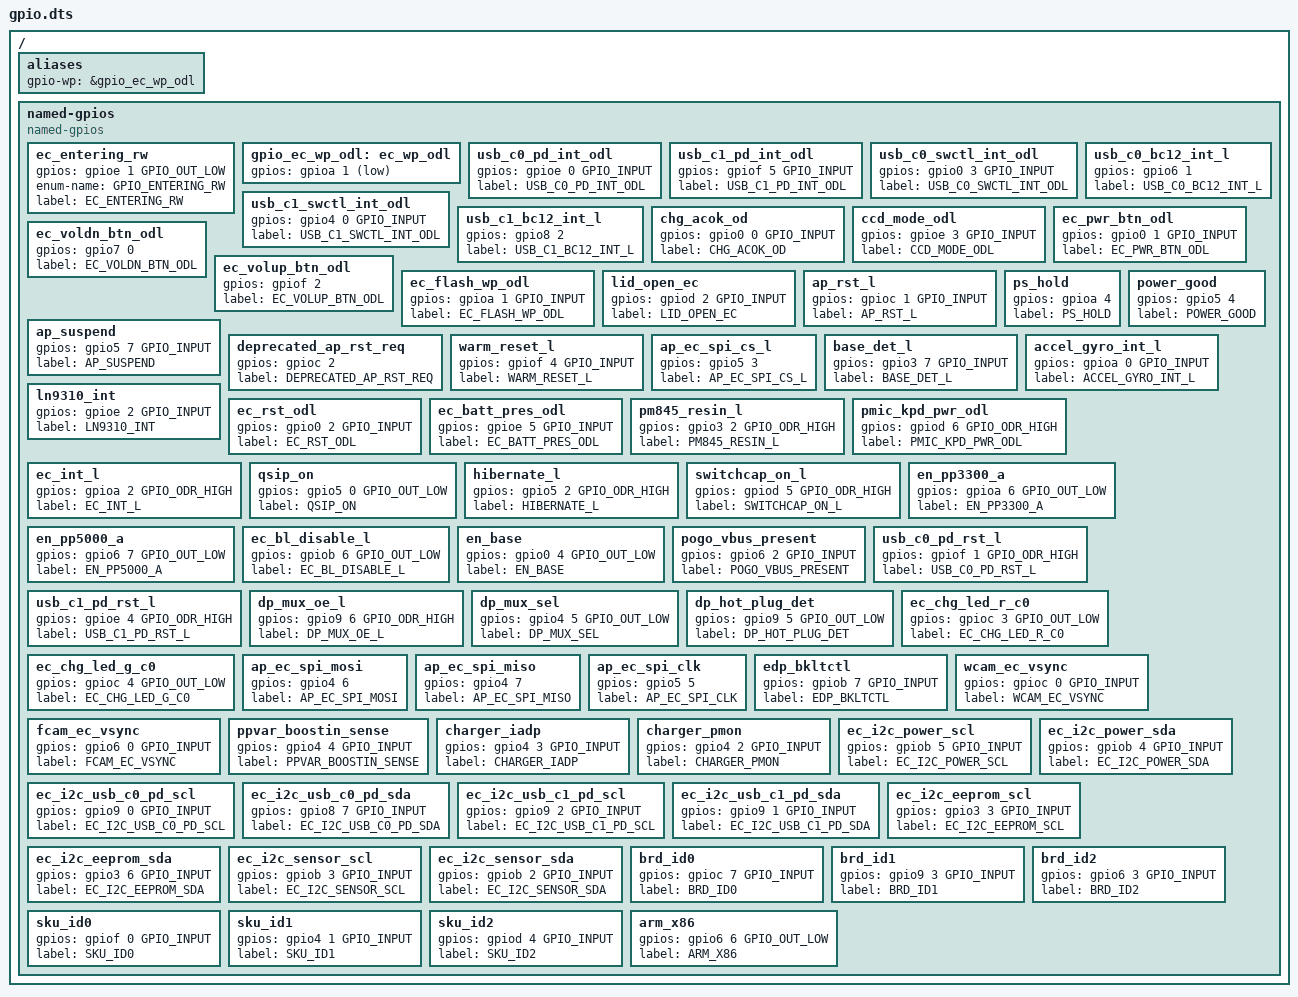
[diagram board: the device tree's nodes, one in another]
/* Copyright 2022 The Chromium OS Authors. All rights reserved.
 * Use of this source code is governed by a BSD-style license that can be
 * found in the LICENSE file.
 */

/ {
	aliases {
		gpio-wp = &gpio_ec_wp_odl;
	};

	named-gpios {
		compatible = "named-gpios";

		ec_entering_rw {
			gpios = <&gpioe 1 GPIO_OUTPUT_LOW>;
			enum-name = "GPIO_ENTERING_RW";
		};
		gpio_ec_wp_odl: ec_wp_odl {
			gpios = <&gpioa 1 (GPIO_INPUT | GPIO_ACTIVE_LOW)>;
		};
		usb_c0_pd_int_odl {
			gpios = <&gpioe 0 GPIO_INPUT>;
			label = "USB_C0_PD_INT_ODL";
		};
		usb_c1_pd_int_odl {
			gpios = <&gpiof 5 GPIO_INPUT>;
			label = "USB_C1_PD_INT_ODL";
		};
		usb_c0_swctl_int_odl {
			gpios = <&gpio0 3 GPIO_INPUT>;
			label = "USB_C0_SWCTL_INT_ODL";
		};
		usb_c1_swctl_int_odl {
			gpios = <&gpio4 0 GPIO_INPUT>;
			label = "USB_C1_SWCTL_INT_ODL";
		};
		usb_c0_bc12_int_l {
			gpios = <&gpio6 1 (GPIO_INPUT | GPIO_PULL_UP)>;
			label = "USB_C0_BC12_INT_L";
		};
		usb_c1_bc12_int_l {
			gpios = <&gpio8 2 (GPIO_INPUT | GPIO_PULL_UP)>;
			label = "USB_C1_BC12_INT_L";
		};
		chg_acok_od {
			gpios = <&gpio0 0 GPIO_INPUT>;
			label = "CHG_ACOK_OD";
		};
		ccd_mode_odl {
			gpios = <&gpioe 3 GPIO_INPUT>;
			label = "CCD_MODE_ODL";
		};
		ec_pwr_btn_odl {
			gpios = <&gpio0 1 GPIO_INPUT>;
			label = "EC_PWR_BTN_ODL";
		};
		ec_voldn_btn_odl {
			gpios = <&gpio7 0 (GPIO_INPUT | GPIO_PULL_UP)>;
			label = "EC_VOLDN_BTN_ODL";
		};
		ec_volup_btn_odl {
			gpios = <&gpiof 2 (GPIO_INPUT | GPIO_PULL_UP)>;
			label = "EC_VOLUP_BTN_ODL";
		};
		ec_flash_wp_odl {
			gpios = <&gpioa 1 GPIO_INPUT>;
			label = "EC_FLASH_WP_ODL";
		};
		lid_open_ec {
			gpios = <&gpiod 2 GPIO_INPUT>;
			label = "LID_OPEN_EC";
		};
		ap_rst_l {
			gpios = <&gpioc 1 GPIO_INPUT>;
			label = "AP_RST_L";
		};
		ps_hold {
			gpios = <&gpioa 4 (GPIO_INPUT | GPIO_PULL_DOWN)>;
			label = "PS_HOLD";
		};
		ap_suspend {
			gpios = <&gpio5 7 GPIO_INPUT>;
			label = "AP_SUSPEND";
		};
		deprecated_ap_rst_req {
			gpios = <&gpioc 2 (GPIO_INPUT | GPIO_PULL_DOWN)>;
			label = "DEPRECATED_AP_RST_REQ";
		};
		power_good {
			gpios = <&gpio5 4 (GPIO_INPUT | GPIO_PULL_DOWN)>;
			label = "POWER_GOOD";
		};
		warm_reset_l {
			gpios = <&gpiof 4 GPIO_INPUT>;
			label = "WARM_RESET_L";
		};
		ap_ec_spi_cs_l {
			gpios = <&gpio5 3 (GPIO_INPUT | GPIO_PULL_DOWN)>;
			label = "AP_EC_SPI_CS_L";
		};
		base_det_l {
			gpios = <&gpio3 7 GPIO_INPUT>;
			label = "BASE_DET_L";
		};
		accel_gyro_int_l {
			gpios = <&gpioa 0 GPIO_INPUT>;
			label = "ACCEL_GYRO_INT_L";
		};
		ln9310_int {
			gpios = <&gpioe 2 GPIO_INPUT>;
			label = "LN9310_INT";
		};
		ec_rst_odl {
			gpios = <&gpio0 2 GPIO_INPUT>;
			label = "EC_RST_ODL";
		};
		ec_entering_rw {
			gpios = <&gpioe 1 GPIO_OUT_LOW>;
			label = "EC_ENTERING_RW";
		};
		ec_batt_pres_odl {
			gpios = <&gpioe 5 GPIO_INPUT>;
			label = "EC_BATT_PRES_ODL";
		};
		pm845_resin_l {
			gpios = <&gpio3 2 GPIO_ODR_HIGH>;
			label = "PM845_RESIN_L";
		};
		pmic_kpd_pwr_odl {
			gpios = <&gpiod 6 GPIO_ODR_HIGH>;
			label = "PMIC_KPD_PWR_ODL";
		};
		ec_int_l {
			gpios = <&gpioa 2 GPIO_ODR_HIGH>;
			label = "EC_INT_L";
		};
		qsip_on {
			gpios = <&gpio5 0 GPIO_OUT_LOW>;
			label = "QSIP_ON";
		};
		hibernate_l {
			gpios = <&gpio5 2 GPIO_ODR_HIGH>;
			label = "HIBERNATE_L";
		};
		switchcap_on_l {
			gpios = <&gpiod 5 GPIO_ODR_HIGH>;
			label = "SWITCHCAP_ON_L";
		};
		en_pp3300_a {
			gpios = <&gpioa 6 GPIO_OUT_LOW>;
			label = "EN_PP3300_A";
		};
		en_pp5000_a {
			gpios = <&gpio6 7 GPIO_OUT_LOW>;
			label = "EN_PP5000_A";
		};
		ec_bl_disable_l {
			gpios = <&gpiob 6 GPIO_OUT_LOW>;
			label = "EC_BL_DISABLE_L";
		};
		en_base {
			gpios = <&gpio0 4 GPIO_OUT_LOW>;
			label = "EN_BASE";
		};
		pogo_vbus_present {
			gpios = <&gpio6 2 GPIO_INPUT>;
			label = "POGO_VBUS_PRESENT";
		};
		usb_c0_pd_rst_l {
			gpios = <&gpiof 1 GPIO_ODR_HIGH>;
			label = "USB_C0_PD_RST_L";
		};
		usb_c1_pd_rst_l {
			gpios = <&gpioe 4 GPIO_ODR_HIGH>;
			label = "USB_C1_PD_RST_L";
		};
		dp_mux_oe_l {
			gpios = <&gpio9 6 GPIO_ODR_HIGH>;
			label = "DP_MUX_OE_L";
		};
		dp_mux_sel {
			gpios = <&gpio4 5 GPIO_OUT_LOW>;
			label = "DP_MUX_SEL";
		};
		dp_hot_plug_det {
			gpios = <&gpio9 5 GPIO_OUT_LOW>;
			label = "DP_HOT_PLUG_DET";
		};
		ec_chg_led_r_c0 {
			gpios = <&gpioc 3 GPIO_OUT_LOW>;
			label = "EC_CHG_LED_R_C0";
		};
		ec_chg_led_g_c0 {
			gpios = <&gpioc 4 GPIO_OUT_LOW>;
			label = "EC_CHG_LED_G_C0";
		};
		ap_ec_spi_mosi {
			gpios = <&gpio4 6 (GPIO_INPUT | GPIO_PULL_DOWN)>;
			label = "AP_EC_SPI_MOSI";
		};
		ap_ec_spi_miso {
			gpios = <&gpio4 7 (GPIO_INPUT | GPIO_PULL_DOWN)>;
			label = "AP_EC_SPI_MISO";
		};
		ap_ec_spi_clk {
			gpios = <&gpio5 5 (GPIO_INPUT | GPIO_PULL_DOWN)>;
			label = "AP_EC_SPI_CLK";
		};
		edp_bkltctl {
			gpios = <&gpiob 7 GPIO_INPUT>;
			label = "EDP_BKLTCTL";
		};
		wcam_ec_vsync {
			gpios = <&gpioc 0 GPIO_INPUT>;
			label = "WCAM_EC_VSYNC";
		};
		fcam_ec_vsync {
			gpios = <&gpio6 0 GPIO_INPUT>;
			label = "FCAM_EC_VSYNC";
		};
		ppvar_boostin_sense {
			gpios = <&gpio4 4 GPIO_INPUT>;
			label = "PPVAR_BOOSTIN_SENSE";
		};
		charger_iadp {
			gpios = <&gpio4 3 GPIO_INPUT>;
			label = "CHARGER_IADP";
		};
		charger_pmon {
			gpios = <&gpio4 2 GPIO_INPUT>;
			label = "CHARGER_PMON";
		};
		ec_i2c_power_scl {
			gpios = <&gpiob 5 GPIO_INPUT>;
			label = "EC_I2C_POWER_SCL";
		};
		ec_i2c_power_sda {
			gpios = <&gpiob 4 GPIO_INPUT>;
			label = "EC_I2C_POWER_SDA";
		};
		ec_i2c_usb_c0_pd_scl {
			gpios = <&gpio9 0 GPIO_INPUT>;
			label = "EC_I2C_USB_C0_PD_SCL";
		};
		ec_i2c_usb_c0_pd_sda {
			gpios = <&gpio8 7 GPIO_INPUT>;
			label = "EC_I2C_USB_C0_PD_SDA";
		};
		ec_i2c_usb_c1_pd_scl {
			gpios = <&gpio9 2 GPIO_INPUT>;
			label = "EC_I2C_USB_C1_PD_SCL";
		};
		ec_i2c_usb_c1_pd_sda {
			gpios = <&gpio9 1 GPIO_INPUT>;
			label = "EC_I2C_USB_C1_PD_SDA";
		};
		ec_i2c_eeprom_scl {
			gpios = <&gpio3 3 GPIO_INPUT>;
			label = "EC_I2C_EEPROM_SCL";
		};
		ec_i2c_eeprom_sda {
			gpios = <&gpio3 6 GPIO_INPUT>;
			label = "EC_I2C_EEPROM_SDA";
		};
		ec_i2c_sensor_scl {
			gpios = <&gpiob 3 GPIO_INPUT>;
			label = "EC_I2C_SENSOR_SCL";
		};
		ec_i2c_sensor_sda {
			gpios = <&gpiob 2 GPIO_INPUT>;
			label = "EC_I2C_SENSOR_SDA";
		};
		brd_id0 {
			gpios = <&gpioc 7 GPIO_INPUT>;
			label = "BRD_ID0";
		};
		brd_id1 {
			gpios = <&gpio9 3 GPIO_INPUT>;
			label = "BRD_ID1";
		};
		brd_id2 {
			gpios = <&gpio6 3 GPIO_INPUT>;
			label = "BRD_ID2";
		};
		sku_id0 {
			gpios = <&gpiof 0 GPIO_INPUT>;
			label = "SKU_ID0";
		};
		sku_id1 {
			gpios = <&gpio4 1 GPIO_INPUT>;
			label = "SKU_ID1";
		};
		sku_id2 {
			gpios = <&gpiod 4 GPIO_INPUT>;
			label = "SKU_ID2";
		};
		arm_x86 {
			gpios = <&gpio6 6 GPIO_OUT_LOW>;
			label = "ARM_X86";
		};
	};
};
